# NPCX498S register map
File version: 1.0
Registers are 8-bit, read-write, reset 0x0 unless marked. A register's access mark holds for its fields unless they carry their own. Offsets are from the block's base; [hi:lo] are bit positions; {n}, {i} and the like mark numbered series.

## SMB0
Base 0x40009000
Same registers: SMB4 0x40008000, SMB1 0x4000B000, SMB5 0x40017000, SMB6 0x40018000, SMB7 0x40019000, SMB2 0x400C0000, SMB3 0x400C2000
0x00 SMBnSDA — SMB Serial Data Register (SMBnSDA)
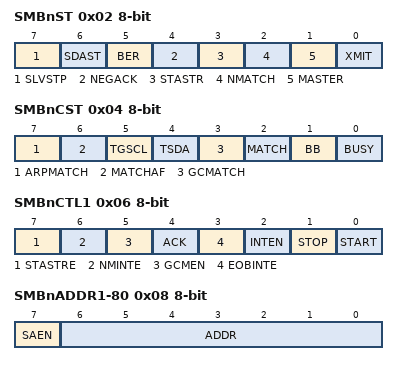
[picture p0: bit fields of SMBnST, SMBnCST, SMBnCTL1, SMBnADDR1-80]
0x02 SMBnST — SMB Status Register (SMBnST)
  [7] SLVSTP — Slave Stop
  [6] SDAST — SDA Status
  [5] BER — Bus Error
  [4] NEGACK — Negative Acknowledge
  [3] STASTR — Stall After Start
  [2] NMATCH — New Match
  [1] MASTER — Master Mode
  [0] XMIT — Transmit Mode
0x04 SMBnCST — SMB Control Status Register (SMBnCST)
  [7] ARPMATCH — ARP Address Match
  [6] MATCHAF — Match Address Field
  [5] TGSCL — Toggle SCL Line
  [4] TSDA — Test SDA Line
  [3] GCMATCH — Global Call Match
  [2] MATCH — Address Match
  [1] BB — Bus Busy
  [0] BUSY — Module Busy
0x06 SMBnCTL1 — SMB Control 1 Register (SMBnCTL1)
  [7] STASTRE — Stall After Start Enable
  [6] NMINTE — New Match Interrupt Enable
  [5] GCMEN — Global Call Match Enable
  [4] ACK — Acknowledge
  [3] EOBINTE — End of Busy Interrupt Enable
  [2] INTEN — Interrupt Enable
  [1] STOP — default
  [0] START — MASTER in SMBnST register is set to 0
0x08 SMBnADDR1-80 — SMB Own Address 1 - 8 Register (SMBnADDR1-8)
  [7] SAEN — Slave Address Enable
  [6:0] ADDR — Address
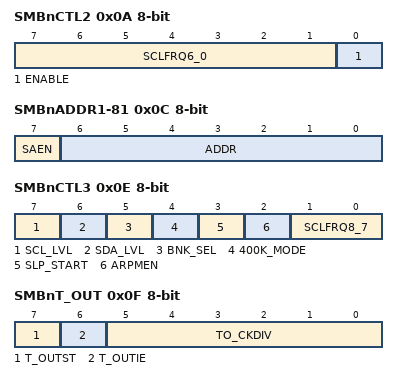
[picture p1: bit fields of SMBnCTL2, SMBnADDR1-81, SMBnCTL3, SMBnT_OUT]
0x0A SMBnCTL2 — SMB Control 2 Register (SMBnCTL2)
  [7:1] SCLFRQ6_0 — SCL Frequency bits 6 through 0
  [0] ENABLE — default
0x0C SMBnADDR1-81 — SMB Own Address 1 - 8 Register (SMBnADDR1-8)
  [7] SAEN — Slave Address Enable
  [6:0] ADDR — Address
0x0E SMBnCTL3 — SMB Control 3 Register (SMBnCTL3)
  [7] SCL_LVL — SCL Level
  [6] SDA_LVL — SDA Level
  [5] BNK_SEL — Bank Select
  [4] 400K_MODE — 400 KHz Master Enable
  [3] SLP_START — Start Detect in Sleep Enable
  [2] ARPMEN — ARP Match Enable
  [1:0] SCLFRQ8_7 — SCL Frequency bits 8 and 7
0x0F SMBnT_OUT — SMB Bus Timeout Register (SMBnT_OUT)
  [7] T_OUTST — Timeout Status
  [6] T_OUTIE — Timeout Interrupt Enable
  [5:0] TO_CKDIV — Timeout Clock Divisor
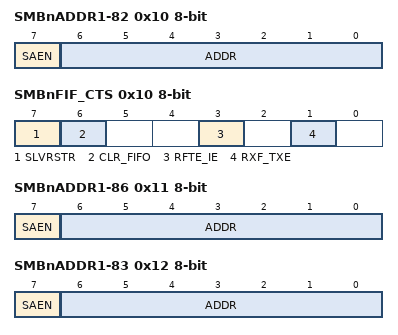
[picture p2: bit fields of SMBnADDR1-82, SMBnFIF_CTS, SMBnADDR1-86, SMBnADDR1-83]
0x10 SMBnADDR1-82 — SMB Own Address 1 - 8 Register (SMBnADDR1-8)
  [7] SAEN — Slave Address Enable
  [6:0] ADDR — Address
0x10 SMBnFIF_CTS — SMB FIFO Control and Status Register (SMBnFIF_CTS)
  [7] SLVRSTR — Slave Start or Restart
  [6] CLR_FIFO — Clear FIFOs
  [3] RFTE_IE — Rx-FIFO Full, Tx-FIFO Empty Interrupt Enable
  [1] RXF_TXE — Rx-FIFO Full, Tx-FIFO Empty Status
0x11 SMBnADDR1-86 — SMB Own Address 1 - 8 Register (SMBnADDR1-8)
  [7] SAEN — Slave Address Enable
  [6:0] ADDR — Address
0x12 SMBnADDR1-83 — SMB Own Address 1 - 8 Register (SMBnADDR1-8)
  [7] SAEN — Slave Address Enable
  [6:0] ADDR — Address
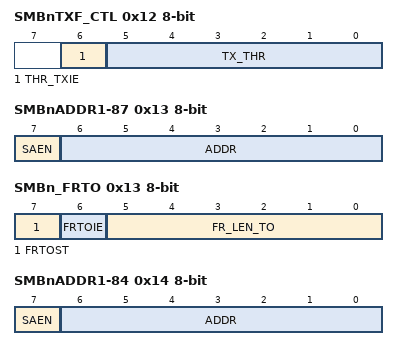
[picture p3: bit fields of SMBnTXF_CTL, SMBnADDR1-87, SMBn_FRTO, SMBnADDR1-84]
0x12 SMBnTXF_CTL — SMB Tx-FIFO Control Register (SMBnTXF_CTL)
  [6] THR_TXIE — Threshold Tx-FIFO Interrupt Enable
  [5:0] TX_THR — Tx-FIFO Threshold
0x13 SMBnADDR1-87 — SMB Own Address 1 - 8 Register (SMBnADDR1-8)
  [7] SAEN — Slave Address Enable
  [6:0] ADDR — Address
0x13 SMBn_FRTO — SMB Frame Timeout Register (SMBn_FRTO)
  [7] FRTOST — Frame Timeout Status
  [6] FRTOIE — Frame Timeout Interrupt Enable
  [5:0] FR_LEN_TO — Frame Length Timeout
0x14 SMBnADDR1-84 — SMB Own Address 1 - 8 Register (SMBnADDR1-8)
  [7] SAEN — Slave Address Enable
  [6:0] ADDR — Address
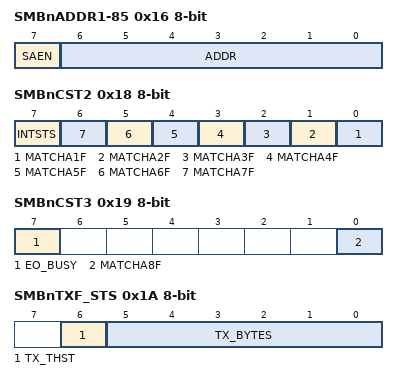
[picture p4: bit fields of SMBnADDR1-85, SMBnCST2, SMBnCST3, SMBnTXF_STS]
0x16 SMBnADDR1-85 — SMB Own Address 1 - 8 Register (SMBnADDR1-8)
  [7] SAEN — Slave Address Enable
  [6:0] ADDR — Address
0x16 SMBnPEC — SMB PEC Register (SMBnPEC)
0x18 SMBnCST2 — SMB Control Status 2 Register (SMBnCST2)
  [7] INTSTS — Interrupt Status
  [n-1] MATCHA{n}F (n=1..7) — Match Address {n} Field
0x19 SMBnCST3 — SMB Control Status 3 Register (SMBnCST3)
  [7] EO_BUSY — End of Busy
  [0] MATCHA8F — Match Address 8 Field
0x1A SMBnTXF_STS — SMB Tx-FIFO Status Register (SMBnTXF_STS)
  [6] TX_THST — Tx-FIFO Threshold Status
  [5:0] TX_BYTES — Tx-FIFO Number of Bytes
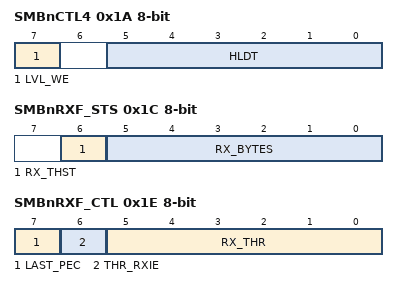
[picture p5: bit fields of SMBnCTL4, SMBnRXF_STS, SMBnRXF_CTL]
0x1A SMBnCTL4 — SMB Control 4 Register (SMBnCTL4)
  [7] LVL_WE — Level Control Write Enable
  [5:0] HLDT — SDA Hold Time
0x1C SMBnSCLLT — SMB SCL Low Time Register (SMBnSCLLT)
0x1C SMBnRXF_STS — SMB Rx-FIFO Status Register (SMBnRXF_STS)
  [6] RX_THST — Rx-FIFO Threshold Status
  [5:0] RX_BYTES — Rx-FIFO Number of Bytes
0x1D SMBnFIF_CTL — SMB FIFO Control Register (SMBnFIF_CTL)
  [4] FIFO_EN — Enable FIFO Mode
0x1E SMBnRXF_CTL — SMB Rx-FIFO Control Register (SMBnRXF_CTL)
  [7] LAST_PEC — Last Byte or PEC Byte
  [6] THR_RXIE — Threshold Rx-FIFO Interrupt Enable
  [5:0] RX_THR — Rx-FIFO Threshold
0x1E SMBnSCLHT — SMB SCL High Time Register (SMBnSCLHT)
